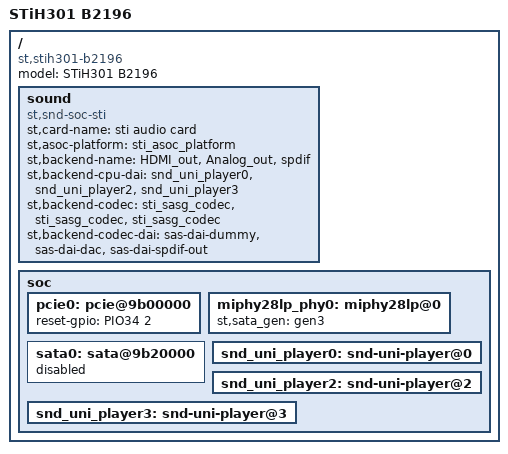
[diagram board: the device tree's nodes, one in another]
/*
 * Copyright (C) 2014 STMicroelectronics Limited.
 * Author: Seraphin Bonnaffe <seraphin.bonnaffe@st.com>
 *
 * This program is free software; you can redistribute it and/or modify
 * it under the terms of the GNU General Public License version 2 as
 * published by the Free Software Foundation.
 */
#include "stih301-b21xx.dts"
/ {
	model = "STiH301 B2196";
	compatible = "st,stih301-b2196", "st,stih301", "st,stih410";

	sound {
		compatible = "st,snd-soc-sti";
		status = "okay";
		st,card-name = "sti audio card";

		st,asoc-platform = <&sti_asoc_platform>;
		st,backend-name  = "HDMI_out", "Analog_out",
				   "spdif";
		st,backend-cpu-dai = <&snd_uni_player0 &snd_uni_player2
				      &snd_uni_player3>;
		st,backend-codec = <&sti_sasg_codec &sti_sasg_codec
				    &sti_sasg_codec>;
		st,backend-codec-dai = "sas-dai-dummy", "sas-dai-dac",
				       "sas-dai-spdif-out";
	};

	soc {
		pcie0: pcie@9b00000{
			status = "okay";
			reset-gpio = <&PIO34 2 0>;
		};

		/*
		 * On B2196, PCIe and SATA are exclusive, and PCIe is enabled
		 * by default. To enable SATA instead, move pcie0 node to
		 * disabled and move sata and miphy nodes below to okay.
		 * Note that SATA usage requires b2136 adaptor.
		 */
		miphy28lp_phy0: miphy28lp@0 {
			/* select internal clock for miphy0 (sata) */
			st,sata_gen = "gen3";
			status = "okay";
		};

		sata0: sata@9b20000 {
			status = "disabled";
		};

		snd_uni_player0: snd-uni-player@0 {
			status = "okay";
		};

		snd_uni_player2: snd-uni-player@2 {
			status = "okay";
		};

		snd_uni_player3: snd-uni-player@3 {
			status = "okay";
		};
	};
};
